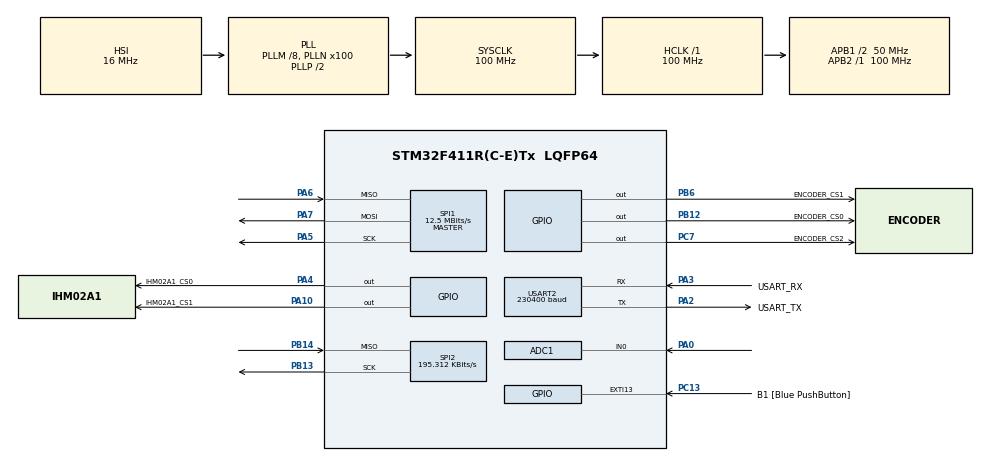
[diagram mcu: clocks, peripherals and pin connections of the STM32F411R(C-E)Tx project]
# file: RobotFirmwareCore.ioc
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ADC1.Channel-0\#ChannelRegularConversion=ADC_CHANNEL_0
ADC1.NbrOfConversionFlag=1
ADC1.Rank-0\#ChannelRegularConversion=1
ADC1.SamplingTime-0\#ChannelRegularConversion=ADC_SAMPLETIME_3CYCLES
ADC1.master=1
Dma.Request0=USART2_RX
Dma.Request1=USART2_TX
Dma.USART2_RX.0.Direction=DMA_PERIPH_TO_MEMORY
Dma.USART2_RX.0.FIFOMode=DMA_FIFOMODE_DISABLE
Dma.USART2_RX.0.Instance=DMA1_Stream7
Dma.USART2_RX.0.MemDataAlignment=DMA_MDATAALIGN_BYTE
Dma.USART2_RX.0.MemInc=DMA_MINC_ENABLE
Dma.USART2_RX.0.Mode=DMA_NORMAL
Dma.USART2_RX.0.PeriphDataAlignment=DMA_PDATAALIGN_BYTE
Dma.USART2_RX.0.PeriphInc=DMA_PINC_DISABLE
Dma.USART2_RX.0.Priority=DMA_PRIORITY_HIGH
Dma.USART2_TX.1.Direction=DMA_MEMORY_TO_PERIPH
Dma.USART2_TX.1.FIFOMode=DMA_FIFOMODE_DISABLE
Dma.USART2_TX.1.Instance=DMA1_Stream6
Dma.USART2_TX.1.MemDataAlignment=DMA_MDATAALIGN_BYTE
Dma.USART2_TX.1.MemInc=DMA_MINC_ENABLE
Dma.USART2_TX.1.Mode=DMA_NORMAL
Dma.USART2_TX.1.PeriphDataAlignment=DMA_PDATAALIGN_BYTE
Dma.USART2_TX.1.PeriphInc=DMA_PINC_DISABLE
Dma.USART2_TX.1.Priority=DMA_PRIORITY_HIGH
Mcu.Family=STM32F4
Mcu.Name=STM32F411R(C-E)Tx
Mcu.Package=LQFP64
NVIC.DMA1_Stream6_IRQn=true\:0\:0\:false\:false\:true\:false
NVIC.DMA1_Stream7_IRQn=true\:0\:0\:false\:false\:true\:false
NVIC.PriorityGroup=NVIC_PRIORITYGROUP_0
NVIC.TIM1_UP_TIM10_IRQn=true\:0\:0\:false\:false\:true\:false
NVIC.TIM3_IRQn=true\:0\:0\:false\:false\:true\:true
NVIC.TIM4_IRQn=true\:0\:0\:false\:false\:true\:true
NVIC.TIM5_IRQn=true\:0\:0\:false\:false\:true\:true
NVIC.TimeBase=TIM1_UP_TIM10_IRQn
NVIC.TimeBaseIP=TIM1
NVIC.USART2_IRQn=true\:0\:0\:false\:false\:true\:true
PA0-WKUP.Signal=ADCx_IN0
PA10.GPIO_Label=IHM02A1_CS1
PA10.GPIO_Speed=GPIO_SPEED_FREQ_VERY_HIGH
PA10.Signal=GPIO_Output
PA13.GPIO_Label=TMS
PA13.Mode=Serial_Wire
PA13.Signal=SYS_JTMS-SWDIO
PA14.GPIO_Label=TCK
PA14.Mode=Serial_Wire
PA14.Signal=SYS_JTCK-SWCLK
PA2.GPIO_Label=USART_TX
PA2.Mode=Asynchronous
PA2.Signal=USART2_TX
PA3.GPIO_Label=USART_RX
PA3.Mode=Asynchronous
PA3.Signal=USART2_RX
PA4.GPIO_Label=IHM02A1_CS0
PA4.GPIO_Speed=GPIO_SPEED_FREQ_VERY_HIGH
PA4.Signal=GPIO_Output
PA5.Mode=Full_Duplex_Master
PA5.Signal=SPI1_SCK
PA6.Mode=Full_Duplex_Master
PA6.Signal=SPI1_MISO
PA7.Mode=Full_Duplex_Master
PA7.Signal=SPI1_MOSI
PB12.GPIO_Label=ENCODER_CS0
PB12.GPIO_Speed=GPIO_SPEED_FREQ_HIGH
PB12.PinState=GPIO_PIN_SET
PB12.Signal=GPIO_Output
PB13.Mode=RX_Only_Simplex_Unidirect_Master
PB13.Signal=SPI2_SCK
PB14.Mode=RX_Only_Simplex_Unidirect_Master
PB14.Signal=SPI2_MISO
PB3.GPIO_Label=SWO
PB3.Signal=SYS_JTDO-SWO
PB6.GPIO_Label=ENCODER_CS1
PB6.GPIO_Speed=GPIO_SPEED_FREQ_HIGH
PB6.PinState=GPIO_PIN_SET
PB6.Signal=GPIO_Output
PC13-ANTI_TAMP.GPIO_Label=B1 [Blue PushButton]
PC13-ANTI_TAMP.GPIO_ModeDefaultEXTI=GPIO_MODE_IT_FALLING
PC13-ANTI_TAMP.Signal=GPXTI13
PC14-OSC32_IN.Mode=LSE-External-Oscillator
PC14-OSC32_IN.Signal=RCC_OSC32_IN
PC15-OSC32_OUT.Mode=LSE-External-Oscillator
PC15-OSC32_OUT.Signal=RCC_OSC32_OUT
PC7.GPIO_Label=ENCODER_CS2
PC7.GPIO_Speed=GPIO_SPEED_FREQ_HIGH
PC7.PinState=GPIO_PIN_SET
PC7.Signal=GPIO_Output
PH0\ -\ OSC_IN.Mode=HSE-External-Clock-Source
PH0\ -\ OSC_IN.Signal=RCC_OSC_IN
PH1\ -\ OSC_OUT.Mode=HSE-External-Clock-Source
PH1\ -\ OSC_OUT.Signal=RCC_OSC_OUT
ProjectManager.HeapSize=0x200
ProjectManager.StackSize=0x400
ProjectManager.TargetToolchain=SW4STM32
RCC.48MHZClocksFreq_Value=50000000
RCC.AHBFreq_Value=100000000
RCC.APB1CLKDivider=RCC_HCLK_DIV2
RCC.APB1Freq_Value=50000000
RCC.APB1TimFreq_Value=100000000
RCC.APB2Freq_Value=100000000
RCC.APB2TimFreq_Value=100000000
RCC.CortexFreq_Value=100000000
RCC.FLatency-AdvancedSettings=FLASH_LATENCY_3
RCC.HCLKFreq_Value=100000000
RCC.HSE_VALUE=8000000
RCC.HSI_VALUE=16000000
RCC.PLLM=8
RCC.PLLN=100
RCC.SYSCLKFreq_VALUE=100000000
RCC.SYSCLKSource=RCC_SYSCLKSOURCE_PLLCLK
RCC.VCOOutputFreq_Value=200000000
SH.ADCx_IN0.0=ADC1_IN0,IN0
SPI1.BaudRatePrescaler=SPI_BAUDRATEPRESCALER_8
SPI1.CLKPhase=SPI_PHASE_2EDGE
SPI1.CLKPolarity=SPI_POLARITY_HIGH
SPI1.CalculateBaudRate=12.5 MBits/s
SPI1.Direction=SPI_DIRECTION_2LINES
SPI1.Mode=SPI_MODE_MASTER
SPI1.VirtualType=VM_MASTER
SPI2.BaudRatePrescaler=SPI_BAUDRATEPRESCALER_256
SPI2.CLKPhase=SPI_PHASE_2EDGE
SPI2.CLKPolarity=SPI_POLARITY_HIGH
SPI2.CalculateBaudRate=195.312 KBits/s
SPI2.DataSize=SPI_DATASIZE_16BIT
SPI2.Direction=SPI_DIRECTION_2LINES_RXONLY
SPI2.Mode=SPI_MODE_MASTER
SPI2.VirtualType=VM_MASTER
TIM2.Prescaler=64000-1
TIM3.Period=2000-1
TIM3.Prescaler=50-1
TIM4.Period=500-1
TIM4.Prescaler=1000-1
TIM5.Period=1000-1
TIM5.Prescaler=10000-1
USART2.BaudRate=230400
USART2.VirtualMode=VM_ASYNC
VP_SYS_VS_tim1.Mode=TIM1
VP_TIM2_VS_ClockSourceINT.Mode=Internal
VP_TIM3_VS_ClockSourceINT.Mode=Internal
VP_TIM4_VS_ClockSourceINT.Mode=Internal
VP_TIM5_VS_ClockSourceINT.Mode=Internal
board=NUCLEO-F411RE

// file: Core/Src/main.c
/* USER CODE BEGIN Header */
/**
  ******************************************************************************
  * @file           : main.c
  * @brief          : Main program body
  ******************************************************************************
  ** This notice applies to any and all portions of this file
  * that are not between comment pairs USER CODE BEGIN and
  * USER CODE END. Other portions of this file, whether
  * inserted by the user or by software development tools
  * are owned by their respective copyright owners.
  *
  * COPYRIGHT(c) 2019 STMicroelectronics
  *
  * Redistribution and use in source and binary forms, with or without modification,
  * are permitted provided that the following conditions are met:
  *   1. Redistributions of source code must retain the above copyright notice,
  *      this list of conditions and the following disclaimer.
  *   2. Redistributions in binary form must reproduce the above copyright notice,
  *      this list of conditions and the following disclaimer in the documentation
  *      and/or other materials provided with the distribution.
  *   3. Neither the name of STMicroelectronics nor the names of its contributors
  *      may be used to endorse or promote products derived from this software
  *      without specific prior written permission.
  *
  * THIS SOFTWARE IS PROVIDED BY THE COPYRIGHT HOLDERS AND CONTRIBUTORS "AS IS"
  * AND ANY EXPRESS OR IMPLIED WARRANTIES, INCLUDING, BUT NOT LIMITED TO, THE
  * IMPLIED WARRANTIES OF MERCHANTABILITY AND FITNESS FOR A PARTICULAR PURPOSE ARE
  * DISCLAIMED. IN NO EVENT SHALL THE COPYRIGHT HOLDER OR CONTRIBUTORS BE LIABLE
  * FOR ANY DIRECT, INDIRECT, INCIDENTAL, SPECIAL, EXEMPLARY, OR CONSEQUENTIAL
  * DAMAGES (INCLUDING, BUT NOT LIMITED TO, PROCUREMENT OF SUBSTITUTE GOODS OR
  * SERVICES; LOSS OF USE, DATA, OR PROFITS; OR BUSINESS INTERRUPTION) HOWEVER
  * CAUSED AND ON ANY THEORY OF LIABILITY, WHETHER IN CONTRACT, STRICT LIABILITY,
  * OR TORT (INCLUDING NEGLIGENCE OR OTHERWISE) ARISING IN ANY WAY OUT OF THE USE
  * OF THIS SOFTWARE, EVEN IF ADVISED OF THE POSSIBILITY OF SUCH DAMAGE.
  *
  ******************************************************************************
  */
/* USER CODE END Header */

#include "main.h"
#include "adc.h"
#include "dma.h"
#include "spi.h"
#include "tim.h"
#include "usart.h"
#include "gpio.h"

/* USER CODE BEGIN PV */
/* Private variables ---------------------------------------------------------*/

/* USER CODE END PV */

void SystemClock_Config(void);
/* USER CODE BEGIN PFP */
/* Private function prototypes -----------------------------------------------*/

/* USER CODE END PFP */

int main(void)
{

  /* MCU Configuration--------------------------------------------------------*/

  /* Reset of all peripherals, Initializes the Flash interface and the Systick. */
  HAL_Init();

  /* Configure the system clock */
  SystemClock_Config();

  /* Initialize all configured peripherals */
  MX_GPIO_Init();
  MX_DMA_Init();
  MX_USART2_UART_Init();
  MX_ADC1_Init();
  MX_TIM2_Init();
  MX_TIM3_Init();
  MX_TIM4_Init();
  MX_SPI2_Init();
  MX_SPI1_Init();
  MX_TIM5_Init();
  /* USER CODE BEGIN 2 */
  BSP_Init();

  setup();
  /* USER CODE END 2 */

  /* Infinite loop */
  /* USER CODE BEGIN WHILE */
  while (1)
  {
	  loop();

    /* USER CODE END WHILE */

  }
}

void SystemClock_Config(void)
{
  RCC_OscInitTypeDef RCC_OscInitStruct = {0};
  RCC_ClkInitTypeDef RCC_ClkInitStruct = {0};

  /**Configure the main internal regulator output voltage
  */
  __HAL_RCC_PWR_CLK_ENABLE();
  __HAL_PWR_VOLTAGESCALING_CONFIG(PWR_REGULATOR_VOLTAGE_SCALE1);
  /**Initializes the CPU, AHB and APB busses clocks
  */
  RCC_OscInitStruct.OscillatorType = RCC_OSCILLATORTYPE_HSI;
  RCC_OscInitStruct.HSIState = RCC_HSI_ON;
  RCC_OscInitStruct.HSICalibrationValue = RCC_HSICALIBRATION_DEFAULT;
  RCC_OscInitStruct.PLL.PLLState = RCC_PLL_ON;
  RCC_OscInitStruct.PLL.PLLSource = RCC_PLLSOURCE_HSI;
  RCC_OscInitStruct.PLL.PLLM = 8;
  RCC_OscInitStruct.PLL.PLLN = 100;
  RCC_OscInitStruct.PLL.PLLP = RCC_PLLP_DIV2;
  RCC_OscInitStruct.PLL.PLLQ = 4;
  if (HAL_RCC_OscConfig(&RCC_OscInitStruct) != HAL_OK)
  {
    Error_Handler();
  }
  /**Initializes the CPU, AHB and APB busses clocks
  */
  RCC_ClkInitStruct.ClockType = RCC_CLOCKTYPE_HCLK|RCC_CLOCKTYPE_SYSCLK
                              |RCC_CLOCKTYPE_PCLK1|RCC_CLOCKTYPE_PCLK2;
  RCC_ClkInitStruct.SYSCLKSource = RCC_SYSCLKSOURCE_PLLCLK;
  RCC_ClkInitStruct.AHBCLKDivider = RCC_SYSCLK_DIV1;
  RCC_ClkInitStruct.APB1CLKDivider = RCC_HCLK_DIV2;
  RCC_ClkInitStruct.APB2CLKDivider = RCC_HCLK_DIV1;

  if (HAL_RCC_ClockConfig(&RCC_ClkInitStruct, FLASH_LATENCY_3) != HAL_OK)
  {
    Error_Handler();
  }
}

void HAL_TIM_PeriodElapsedCallback(TIM_HandleTypeDef *htim)
{
  if (htim->Instance == TIM1) {
    HAL_IncTick();
  }
  /* USER CODE BEGIN Callback 1 */
  if (htim->Instance == TIM3){
	  TIM3_PeriodElapsedCallback();
  }else if (htim->Instance == TIM4){
	  TIM4_PeriodElapsedCallback();
  }else if (htim->Instance == TIM5){
	  TIM5_PeriodElapsedCallback();
  }
  /* USER CODE END Callback 1 */
}

void Error_Handler(void)
{
  while(1)
  {
  }
}

/************************ (C) COPYRIGHT STMicroelectronics *****END OF FILE****/
